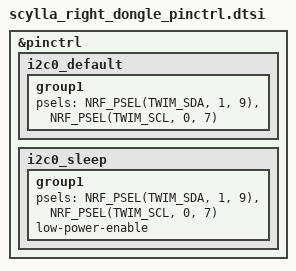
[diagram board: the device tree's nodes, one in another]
&pinctrl {
        i2c0_default: i2c0_default {
              group1 {
                      psels = <NRF_PSEL(TWIM_SDA, 1, 9)>, // 21 on the left side
                              <NRF_PSEL(TWIM_SCL, 0, 7)>; //19 for the onboard
              };
           };

           i2c0_sleep: i2c0_sleep {
              group1 {
                      psels = <NRF_PSEL(TWIM_SDA, 1, 9)>, // 21 on the left side
                              <NRF_PSEL(TWIM_SCL, 0, 7)>; //19 for the onboard
                      low-power-enable;
              };
           };
};
